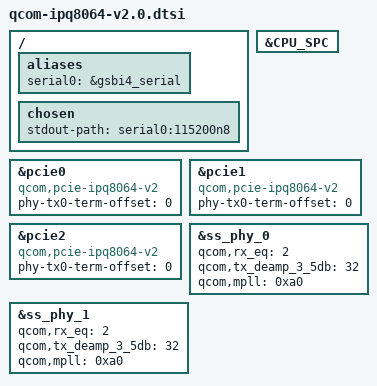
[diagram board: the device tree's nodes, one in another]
#include "qcom-ipq8064.dtsi"

/ {
	aliases {
		serial0 = &gsbi4_serial;
	};

	chosen {
		stdout-path = "serial0:115200n8";
	};
};

&CPU_SPC {
	status = "okay";
};

&pcie0 {
	phy-tx0-term-offset = <0>;
	compatible = "qcom,pcie-ipq8064-v2";
};

&pcie1 {
	phy-tx0-term-offset = <0>;
	compatible = "qcom,pcie-ipq8064-v2";
};

&pcie2 {
	phy-tx0-term-offset = <0>;
	compatible = "qcom,pcie-ipq8064-v2";
};

&ss_phy_0 {
	qcom,rx_eq = <2>;
	qcom,tx_deamp_3_5db = <32>;
	qcom,mpll = <0xa0>;
};

&ss_phy_1 {
	qcom,rx_eq = <2>;
	qcom,tx_deamp_3_5db = <32>;
	qcom,mpll = <0xa0>;
};
